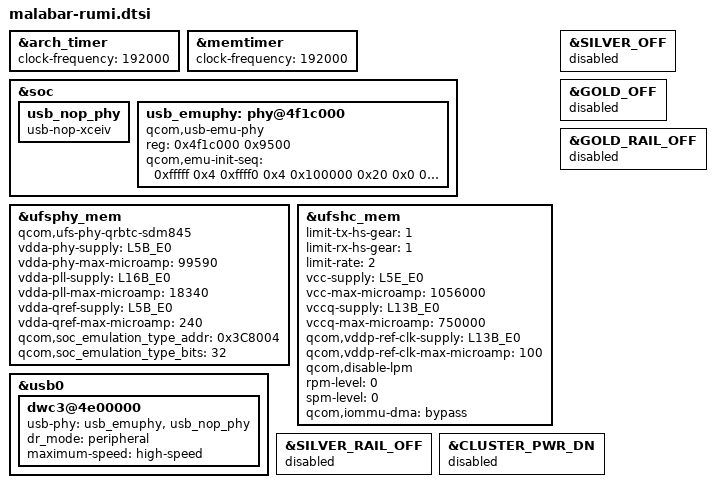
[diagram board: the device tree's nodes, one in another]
// SPDX-License-Identifier: BSD-3-Clause
/*
 * Copyright (c) Qualcomm Technologies, Inc. and/or its subsidiaries.
 */
&arch_timer {
	clock-frequency = <192000>;
};

&memtimer {
	clock-frequency = <192000>;
};

&soc {
	usb_nop_phy: usb_nop_phy {
		compatible = "usb-nop-xceiv";
	};

	usb_emuphy: phy@4f1c000 {
		compatible = "qcom,usb-emu-phy";
		reg = <0x4f1c000 0x9500>;

		qcom,emu-init-seq = <0xfffff 0x4
			0xffff0 0x4
			0x100000 0x20
			0x0 0x20
			0x000101F0 0x20
			0x00100000 0x3c
			0x0 0x3c
			0x0 0x4>;
	};
};

&ufsphy_mem {
	compatible = "qcom,ufs-phy-qrbtc-sdm845";
	/* VDDA_UFS_CORE */
	vdda-phy-supply	= <&L5B_E0>;
	vdda-phy-max-microamp =	<99590>;

	/* VDDA_UFS_0_1P2 */
	vdda-pll-supply	= <&L16B_E0>;
	vdda-pll-max-microamp =	<18340>;

	/* Qref power supply, Refer Qref diagram */
	vdda-qref-supply = <&L5B_E0>;
	vdda-qref-max-microamp = <240>;

	/* Detect whether RH132 card based sequences to be used */
	qcom,soc_emulation_type_addr = <0x3C8004>;
	qcom,soc_emulation_type_bits = <32>;

	status = "ok";
};

&ufshc_mem {
	limit-tx-hs-gear = <1>;
	limit-rx-hs-gear = <1>;
	limit-rate = <2>; /* HS Rate-B */

	vcc-supply = <&L5E_E0>;
	vcc-max-microamp = <1056000>;

	vccq-supply = <&L13B_E0>;
	vccq-max-microamp = <750000>;

	/* VDD_PX10 is voted for the ufs_reset_n */
	qcom,vddp-ref-clk-supply = <&L13B_E0>;
	qcom,vddp-ref-clk-max-microamp = <100>;

	qcom,disable-lpm;
	rpm-level = <0>;
	spm-level = <0>;

	qcom,iommu-dma = "bypass";

	status = "ok";
};

&usb0 {
	dwc3@4e00000 {
		usb-phy = <&usb_emuphy>, <&usb_nop_phy>;
		dr_mode = "peripheral";
		maximum-speed = "high-speed";
	};
};

&SILVER_OFF {
	status = "disabled";
};

&SILVER_RAIL_OFF {
	status = "disabled";
};

&GOLD_OFF {
	status = "disabled";
};

&GOLD_RAIL_OFF {
	status = "disabled";
};

&CLUSTER_PWR_DN {
	status = "disabled";
};
